# ESP32-H2 register map
Vendor: ESPRESSIF SYSTEMS (SHANGHAI) CO., LTD.; Series: ESP32 H-Series; File version: 11
CPU: RV32IMAC r0p0, little endian, no MPU, no FPU, 0 interrupt priority bits
Address unit: 32 bits
Registers are 32-bit, read-write, reset 0x0 unless marked. A register's access mark holds for its fields unless they carry their own. Offsets are from the block's base; [hi:lo] are bit positions; {n}, {i} and the like mark numbered series.

## OTP_DEBUG — OTP_DEBUG Peripheral
Base 0x600B3C00
0x00 WR_DIS ro — Otp debuger block0 data register1.
  [31:0] BLOCK0_WR_DIS — Otp block0 write disable data.
{0x0+4i} BLK0_BACKUP1_W{i} ro (i=1..5) — Otp debuger block0 data register{i+1}.
  [31:0] OTP_BEBUG_BLOCK0_BACKUP1_W{i} — Otp block0 backup1 word{i} data.
{0x14+4i} BLK0_BACKUP2_W{i} ro (i=1..5) — Otp debuger block0 data register{i+6}.
  [31:0] OTP_BEBUG_BLOCK0_BACKUP2_W{i} — Otp block0 backup2 word{i} data.
{0x28+4i} BLK0_BACKUP3_W{i} ro (i=1..5) — Otp debuger block0 data register{i+11}.
  [31:0] OTP_BEBUG_BLOCK0_BACKUP3_W{i} — Otp block0 backup3 word{i} data.
{0x3C+4i} BLK0_BACKUP4_W{i} ro (i=1..5) — Otp debuger block0 data register{i+16}.
  [31:0] OTP_BEBUG_BLOCK0_BACKUP4_W{i} — Otp block0 backup4 word{i} data.
{0x50+4i} BLK1_W{i} ro (i=1..9) — Otp debuger block1 data register{i}.
  [31:0] BLOCK1_W{i} — Otp block1 word{i} data.
{0x74+4i} BLK2_W{i} ro (i=1..11) — Otp debuger block2 data register{i}.
  [31:0] BLOCK2_W{i} — Otp block2 word{i} data.
{0xA0+4i} BLK3_W{i} ro (i=1..11) — Otp debuger block3 data register{i}.
  [31:0] BLOCK3_W{i} — Otp block3 word{i} data.
{0xCC+4i} BLK4_W{i} ro (i=1..9) — Otp debuger block4 data register{i}.
  [31:0] BLOCK4_W{i} — Otp block4 word{i} data.
0xF4 BLK4_W10 ro — Otp debuger block4 data registe10.
  [31:0] BLOCK4_W10 — Otp block4 word10 data.
0xF8 BLK4_W11 ro — Otp debuger block4 data register11.
  [31:0] BLOCK4_W11 — Otp block4 word11 data.
{0xF8+4i} BLK5_W{i} ro (i=1..11) — Otp debuger block5 data register{i}.
  [31:0] BLOCK5_W{i} — Otp block5 word{i} data.
{0x124+4i} BLK6_W{i} ro (i=1..11) — Otp debuger block6 data register{i}.
  [31:0] BLOCK6_W{i} — Otp block6 word{i} data.
{0x150+4i} BLK7_W{i} ro (i=1..11) — Otp debuger block7 data register{i}.
  [31:0] BLOCK7_W{i} — Otp block7 word{i} data.
{0x17C+4i} BLK8_W{i} ro (i=1..11) — Otp debuger block8 data register{i}.
  [31:0] BLOCK8_W{i} — Otp block8 word{i} data.
{0x1A8+4i} BLK9_W{i} ro (i=1..11) — Otp debuger block9 data register{i}.
  [31:0] BLOCK9_W{i} — Otp block9 word{i} data.
{0x1D4+4i} BLK10_W{i} ro (i=1..9) — Otp debuger block10 data register{i}.
  [31:0] BLOCK10_W{i} — Otp block10 word{i} data.
0x1FC BLK10_W10 ro — Otp debuger block10 data register10.
  [31:0] BLOCK19_W10 — Otp block10 word10 data.
0x200 BLK10_W11 ro — Otp debuger block10 data register11.
  [31:0] BLOCK10_W11 — Otp block10 word11 data.
0x204 CLK — Otp debuger clk_en configuration register.
  [0] EN — Force clock on for this register file.
0x208 APB2OTP_EN — Otp_debuger apb2otp enable configuration register.
  [0] APB2OTP_EN — Debug mode enable signal.
0x20C DATE reset 0x20211028 — eFuse version register.
  [27:0] DATE — Stores otp_debug version.

## PAU — PAU Peripheral
Base 0x60093000
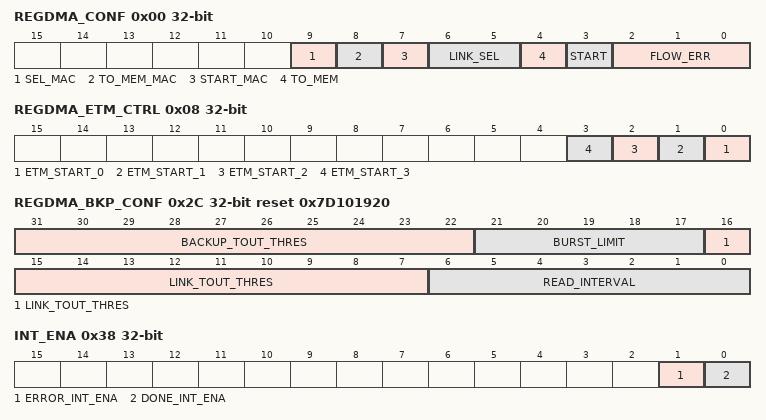
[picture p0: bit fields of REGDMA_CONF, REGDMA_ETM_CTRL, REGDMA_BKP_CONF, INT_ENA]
0x00 REGDMA_CONF access per field — Peri backup control register
  [9] SEL_MAC rw — mac hw/sw select
  [8] TO_MEM_MAC rw — mac sw backup direction(reg to mem / mem to reg)
  [7] START_MAC wo — mac sw backup start signal
  [6:5] LINK_SEL rw — Link select
  [4] TO_MEM rw — backup direction(reg to mem / mem to reg)
  [3] START wo — backup start signal
  [2:0] FLOW_ERR ro — backup error type
0x04 REGDMA_CLK_CONF — Clock control register
  [0] CLK_EN — clock enable
0x08 REGDMA_ETM_CTRL wo — ETM start ctrl reg
  [n] ETM_START_{n} (n=0..3) — etm_start_{n} reg
0x0C REGDMA_LINK_0_ADDR — link_0_addr
  [31:0] LINK_ADDR_0 — link_0_addr reg
{0xC+4i} REGDMA_LINK_{i}_ADDR (i=1..3) — Link_{i}_addr
  [31:0] LINK_ADDR_{i} — Link_{i}_addr reg
0x1C REGDMA_LINK_MAC_ADDR — Link_mac_addr
  [31:0] LINK_ADDR_MAC — Link_mac_addr reg
0x20 REGDMA_CURRENT_LINK_ADDR ro — current link addr
  [31:0] CURRENT_LINK_ADDR — current link addr reg
0x24 REGDMA_BACKUP_ADDR ro — Backup addr
  [31:0] BACKUP_ADDR — backup addr reg
0x28 REGDMA_MEM_ADDR ro — mem addr
  [31:0] MEM_ADDR — mem addr reg
0x2C REGDMA_BKP_CONF reset 0x7D101920 — backup config
  [31:22] BACKUP_TOUT_THRES — Backup timeout threshold
  [21:17] BURST_LIMIT
  [16:7] LINK_TOUT_THRES — link wait timeout threshold
  [6:0] READ_INTERVAL — Link read_interval
0x30 RETENTION_LINK_BASE — retention dma link base
  [26:0] LINK_BASE_ADDR
0x34 RETENTION_CFG reset 0xFFFFFFFF
  [31:0] RET_INV_CFG — retention inv scan out
0x38 INT_ENA — Read only register for error and done
  [1] ERROR_INT_ENA — error flag
  [0] DONE_INT_ENA — backup done flag
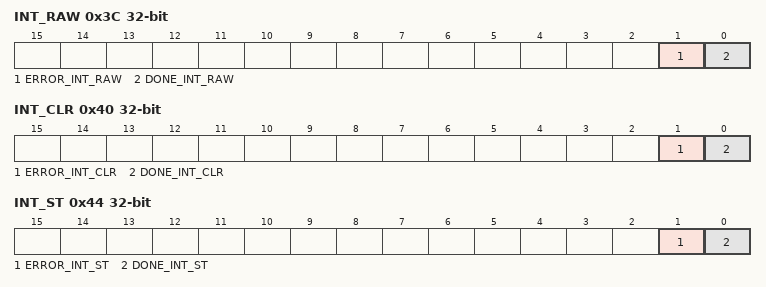
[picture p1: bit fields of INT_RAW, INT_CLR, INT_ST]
0x3C INT_RAW — Read only register for error and done
  [1] ERROR_INT_RAW — error flag
  [0] DONE_INT_RAW — backup done flag
0x40 INT_CLR wo — Read only register for error and done
  [1] ERROR_INT_CLR — error flag
  [0] DONE_INT_CLR — backup done flag
0x44 INT_ST ro — Read only register for error and done
  [1] ERROR_INT_ST — error flag
  [0] DONE_INT_ST — backup done flag
0x3FC DATE reset 0x2203070
  [27:0] DATE — REGDMA date information/ REGDMA version information.
